# CY8C5888LTI_LP097 register map
File version: 0.1
Registers are 8-bit, read-write, no defined reset value unless marked. A register's access mark holds for its fields unless they carry their own. Offsets are from the block's base; [hi:lo] are bit positions; {n}, {i} and the like mark numbered series; 'fields as' and 'values as' point back to an identical list.

## Comp_1
Base 0x00000000
0x400043A7 Comp_1_Comp_PM_ACT_CFG — Active Power Mode Configuration Register 7
  [3:0] en_cmp — Enable comparator. Populated subsystems are counted from the LSB, for example bit 0 corresponds to comparator 0
0x400043B7 Comp_1_Comp_PM_STBY_CFG — Standby Power Mode Configuration Register 7
  fields as Comp_1_Comp_PM_ACT_CFG
0x40004636 Comp_1_Comp_TR0 — Comparator Trim Register_TR0
  [4:0] trimA_4_0_ — Sets the trim value to be added to the P-type load for offset calibration
    0=TRIMA_0 (Does not add any offset); {v}=TRIMA_POS_SIDE_{v} (Adds offset of ~{v}mV to the positive side) (v=1..8); {v}=TRIMA_NEG_SIDE_{v-9} (Adds offset of ~{v-10}mV to the negative side) (v=10..18)
0x40004637 Comp_1_Comp_TR1 — Comparator Trim Register_TR1
  [4:0] trimB_4_0_ — Sets the trim value to be added to the N-type load for offset calibration
    0=TRIMB_0 (Does not add any offset); {v}=TRIMB_NEG_SIDE_{v} (Adds offset of ~{v}mV to the negative side) (v=1..8); 10=TRIMB_9 (Does not add any offset); {v}=TRIMB_POS_SIDE_{v-10} (Adds offset of ~{v-10}mV to the positive side) (v=11..18)
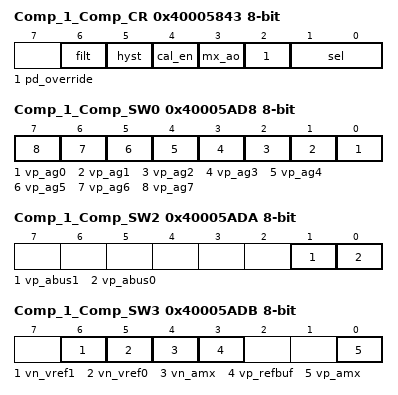
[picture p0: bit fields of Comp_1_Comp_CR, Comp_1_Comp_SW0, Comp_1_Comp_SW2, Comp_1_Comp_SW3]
0x40005843 Comp_1_Comp_CR — Comparator Control Register
  [6] filt — enables a glitch filter at the output of the comparator
    0=FILT_DISABLE (Disable glitch filter); 1=FILT_ENABLE (Enable glitch filter)
  [5] hyst — enables a hysteresis of 10mV typ
    1=HYST_DISABLE (Disable hysteresis); 0=HYST_ENABLE (Enable hysteresis)
  [4] cal_en — enables shorting of the two comparator inputs for trim calibration purposes
    0=CAL_EN_DISABLE (Disable calibration); 1=CAL_EN_ENABLE (Enable calibration)
  [3] mx_ao — comparator sleep always-on logic mux control
    0=MX_AO_BYPASS (Bypass comparator sleep always-on logic); 1=MX_AO_ENABLE (Enable comparator sleep always-on logic)
  [2] pd_override — Power down override to allow comparator to continue operating during sleep
    0=PD_OVERRIDE_DISABLE (Don't override power down); 1=PD_OVERRIDE_ENABLE (Override power down)
  [1:0] sel — Selects the mode of operation of the comparator
    0=SEL_SLOW (slow mode); 1=SEL_FAST (fast mode); 2=SEL_LP (ultra low power mode); 3=SEL_ILLEGAL (Illegal Mode)
0x40005AD8 Comp_1_Comp_SW0 — Comparator Analog Routing Register 0
  [all] fields
    0=AG_NC (not connected); 1=AG_CONNECTED (Connect to Analog Global)
  [n] vp_ag{n} (n=0..7) — Connect positive voltage input to analog global of same side
0x40005ADA Comp_1_Comp_SW2 — Comparator Analog Routing Register 2
  [1] vp_abus1 — Connect positive voltage input to analog (local) bus of the same side
    0=ABUS_NC (not connected); 1=ABUS_CONNECTED (Connect to Analog (local) Bus)
  [0] vp_abus0 — Connect positive voltage input to analog (local) bus of the same side
    values as vp_abus1
0x40005ADB Comp_1_Comp_SW3 — Comparator Analog Routing Register 3
  [6] vn_vref1 — Connect negative voltage input to Voltage Reference 1
    0=VREF_NC (not connected); 1=VREF_CONNECTED (Connect to Voltage Reference)
  [5] vn_vref0 — Connect negative voltage input to Voltage Reference 0
    values as vn_vref1
  [4] vn_amx — Connect negative voltage input to Analog Mux Bus
    0=AMX_NC (not connected); 1=AMX_CONNECTED (Connect to AMUXBUS)
  [3] vp_refbuf — Connect positive voltage input to CapSense reference buffer channel
    0=VP_REFBUF_ENABLED (disable); 1=VP_REFBUF_DISABLED (enable)
  [0] vp_amx — Connect positive voltage input to Analog Mux Bus
    values as vn_amx
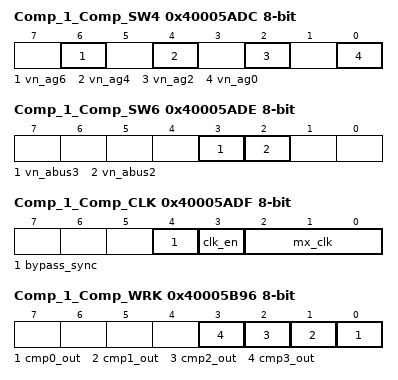
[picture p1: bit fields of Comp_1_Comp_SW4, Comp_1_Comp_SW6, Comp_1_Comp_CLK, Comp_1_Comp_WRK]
0x40005ADC Comp_1_Comp_SW4 — Comparator Analog Routing Register 4
  [all] fields
    values as the fields of Comp_1_Comp_SW0
  [6] vn_ag6 — Connect negative voltage input to analog global of same side
  [4] vn_ag4 — Connect negative voltage input to analog global of same side
  [2] vn_ag2 — Connect negative voltage input to analog global of same side
  [0] vn_ag0 — Connect negative voltage input to analog global of same side
0x40005ADE Comp_1_Comp_SW6 — Comparator Analog Routing Register 6
  [3] vn_abus3 — Connect negative voltage input to analog (local) bus of the same side
    values as Comp_1_Comp_SW2.vp_abus1
  [2] vn_abus2 — Connect negative voltage input to analog (local) bus of the same side
    values as Comp_1_Comp_SW2.vp_abus1
0x40005ADF Comp_1_Comp_CLK — Comparator Clock Control Register
  [4] bypass_sync — Bypass Synchronization
    0=Synchronization not bypassed (Synchronization enabled); 1=Synchronization bypassed (Synchronization disabled)
  [3] clk_en — Clock gating control
    0=disable clock; 1=enable clock
  [2:0] mx_clk — Clock Selection
    {v}=Select clk_a{v} and clk_a{v}_dig (v=0..3); 4=Select UDB generated clock
0x40005B96 Comp_1_Comp_WRK — Comparator output working register
  [n] cmp{n}_out ro (n=0..3) — Comparator Output

## Control_Reg_1
Base 0x00000000
0x40006472 Control_Reg_1_CONTROL_REG

## Timer_2
Base 0x00000000
0x40006504 Timer_2_COUNTER 32-bit — UDB.A0 - Current Down Counter Value
0x40006524 Timer_2_PERIOD 32-bit — UDB.D0 - Assigned Period
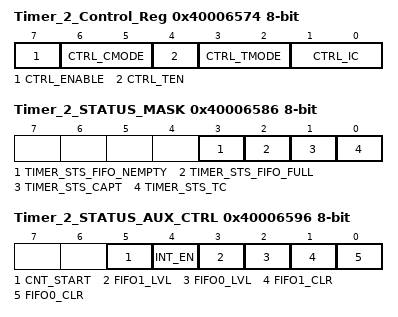
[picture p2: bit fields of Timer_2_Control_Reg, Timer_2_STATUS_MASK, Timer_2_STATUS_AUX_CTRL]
0x40006574 Timer_2_Control_Reg — UDB Control Register - Assigned Control Register Value
  [7] CTRL_ENABLE — Enable the Timer
  [6:5] CTRL_CMODE — Capture Mode
  [4] CTRL_TEN — Trigger Enable Bit
  [3:2] CTRL_TMODE — Trigger Mode
  [1:0] CTRL_IC — Interrupt Count
0x40006586 Timer_2_STATUS_MASK — UDB Status bits Interrupt Mask Enable Register
  [3] TIMER_STS_FIFO_NEMPTY ro — FIFO Empty status
  [2] TIMER_STS_FIFO_FULL ro — FIFO Full Status
  [1] TIMER_STS_CAPT ro — Enables the Interrupt on Capture
  [0] TIMER_STS_TC ro — Enables the Interrupt on TC
0x40006596 Timer_2_STATUS_AUX_CTRL — UDB Auxilliary Control Register
  [5] CNT_START — FIFO0 clear
    0=E_CNT_START0 (Disable counter); 1=E_CNT_START1 (Enable counter)
  [4] INT_EN
    0=E_INT_EN0 (Interrupt disabled); 1=E_INT_EN1 (Interrupt enabled)
  [3] FIFO1_LVL — FIFO level
    0=E_FIFO_LVL_0 (FIFO LVL: input mode: FIFO not full; output mode: FIFO not empty); 1=E_FIFO_LVL_1 (FIFO LVL: input mode: FIFO at least 1/2 empty; output mode: FIFO at least 1/2 full)
  [2] FIFO0_LVL — FIFO level
    values as FIFO1_LVL
  [1] FIFO1_CLR — FIFO1 clear
    0=E_FIFO_CLR_0 (Normal FIFO operation); 1=E_FIFO_CLR_1 (Clear FIFO state)
  [0] FIFO0_CLR — FIFO0 clear
    values as FIFO1_CLR

## UART_1 — UART
Base 0x00000000
0x40006449 TX_UART_1_TX_DATA — TX Data Register
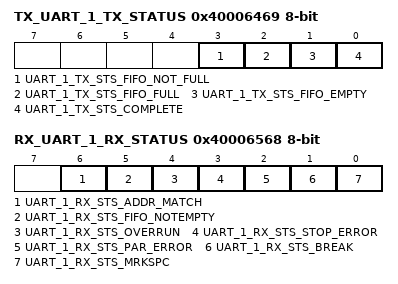
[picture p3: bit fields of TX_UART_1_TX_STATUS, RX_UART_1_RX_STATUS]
0x40006469 TX_UART_1_TX_STATUS — TX status register
  [3] UART_1_TX_STS_FIFO_NOT_FULL ro, [2] UART_1_TX_STS_FIFO_FULL ro, [1] UART_1_TX_STS_FIFO_EMPTY ro, [0] UART_1_TX_STS_COMPLETE ro
0x4000652B RX_UART_1_RX_ADDRESS1 — RX Address1 Register
0x4000653B RX_UART_1_RX_ADDRESS2 — RX Address2 Register
0x4000654B RX_UART_1_RX_DATA — RX Data Register
0x40006568 RX_UART_1_RX_STATUS — RX status register
  [6] UART_1_RX_STS_ADDR_MATCH ro, [5] UART_1_RX_STS_FIFO_NOTEMPTY ro, [4] UART_1_RX_STS_OVERRUN ro, [3] UART_1_RX_STS_STOP_ERROR ro, [2] UART_1_RX_STS_PAR_ERROR ro, [1] UART_1_RX_STS_BREAK ro, [0] UART_1_RX_STS_MRKSPC ro

## Count7_1 — Count7 debug registers
Base 0x00000000
0x40006473 COUNT 7-bit — Count value register
0x40006483 PERIOD 7-bit — Count7 period register
